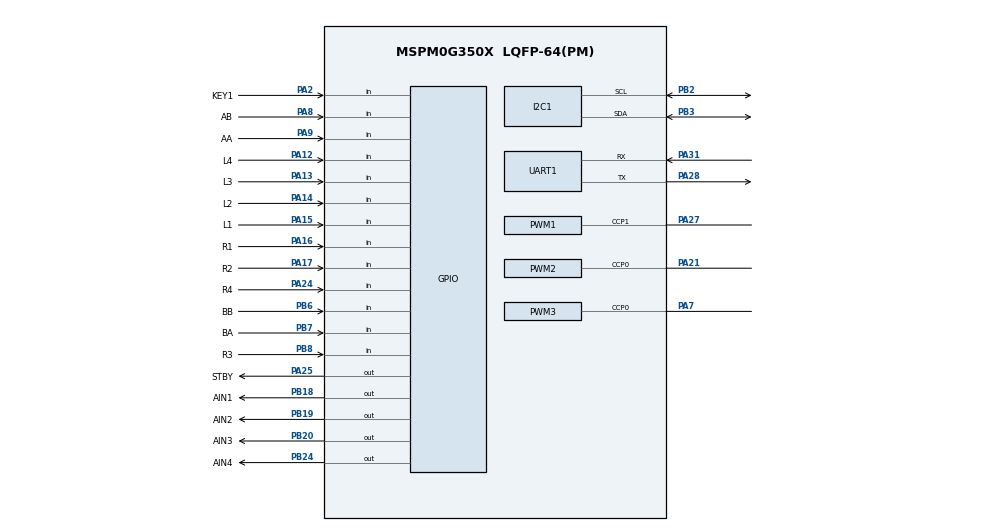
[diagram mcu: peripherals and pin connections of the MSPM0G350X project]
/**
 * @cliArgs --device "MSPM0G350X" --part "Default" --package "LQFP-64(PM)" --product "mspm0_sdk@2.10.00.04"
 * @versions {"tool":"1.26.2+4477"}
 */

/**
 * Import the modules used in this configuration.
 */
const GPIO   = scripting.addModule("/ti/driverlib/GPIO", {}, false);
const GPIO1  = GPIO.addInstance();
const GPIO2  = GPIO.addInstance();
const GPIO3  = GPIO.addInstance();
const GPIO4  = GPIO.addInstance();
const I2C    = scripting.addModule("/ti/driverlib/I2C", {}, false);
const I2C1   = I2C.addInstance();
const I2C2   = I2C.addInstance();
const PWM    = scripting.addModule("/ti/driverlib/PWM", {}, false);
const PWM1   = PWM.addInstance();
const PWM2   = PWM.addInstance();
const PWM3   = PWM.addInstance();
const SYSCTL = scripting.addModule("/ti/driverlib/SYSCTL");
const TIMER  = scripting.addModule("/ti/driverlib/TIMER", {}, false);
const TIMER1 = TIMER.addInstance();
const UART   = scripting.addModule("/ti/driverlib/UART", {}, false);
const UART1  = UART.addInstance();
const VREF   = scripting.addModule("/ti/driverlib/VREF");

/**
 * Write custom configuration values to the imported modules.
 */
const divider9       = system.clockTree["UDIV"];
divider9.divideValue = 2;

const multiplier2         = system.clockTree["PLL_QDIV"];
multiplier2.multiplyValue = 5;

const mux4       = system.clockTree["EXHFMUX"];
mux4.inputSelect = "EXHFMUX_XTAL";

const mux8       = system.clockTree["HSCLKMUX"];
mux8.inputSelect = "HSCLKMUX_SYSPLL0";

const pinFunction4     = system.clockTree["HFXT"];
pinFunction4.inputFreq = 40;
pinFunction4.enable    = true;

GPIO1.$name                              = "KEY";
GPIO1.associatedPins[0].direction        = "INPUT";
GPIO1.associatedPins[0].internalResistor = "PULL_DOWN";
GPIO1.associatedPins[0].interruptEn      = true;
GPIO1.associatedPins[0].polarity         = "RISE";
GPIO1.associatedPins[0].$name            = "KEY1";
GPIO1.associatedPins[0].pin.$assign      = "PA2";

const Board = scripting.addModule("/ti/driverlib/Board", {}, false);

GPIO2.$name                              = "DC_MOTOR_LEFT";
GPIO2.associatedPins.create(5);
GPIO2.associatedPins[0].$name            = "AIN1";
GPIO2.associatedPins[0].pin.$assign      = "PB18";
GPIO2.associatedPins[1].$name            = "AIN2";
GPIO2.associatedPins[1].pin.$assign      = "PB19";
GPIO2.associatedPins[2].$name            = "STBY";
GPIO2.associatedPins[2].pin.$assign      = "PA25";
GPIO2.associatedPins[3].$name            = "AA";
GPIO2.associatedPins[3].direction        = "INPUT";
GPIO2.associatedPins[3].internalResistor = "PULL_DOWN";
GPIO2.associatedPins[3].interruptEn      = true;
GPIO2.associatedPins[3].polarity         = "RISE";
GPIO2.associatedPins[3].pin.$assign      = "PA9";
GPIO2.associatedPins[4].$name            = "AB";
GPIO2.associatedPins[4].direction        = "INPUT";
GPIO2.associatedPins[4].internalResistor = "PULL_DOWN";
GPIO2.associatedPins[4].pin.$assign      = "PA8";

GPIO3.$name                              = "DC_MOTOR_RIGHT";
GPIO3.associatedPins.create(4);
GPIO3.associatedPins[0].$name            = "AIN3";
GPIO3.associatedPins[0].pin.$assign      = "PB20";
GPIO3.associatedPins[1].$name            = "AIN4";
GPIO3.associatedPins[1].pin.$assign      = "PB24";
GPIO3.associatedPins[2].$name            = "BA";
GPIO3.associatedPins[2].direction        = "INPUT";
GPIO3.associatedPins[2].polarity         = "RISE";
GPIO3.associatedPins[2].internalResistor = "PULL_DOWN";
GPIO3.associatedPins[2].interruptEn      = true;
GPIO3.associatedPins[2].pin.$assign      = "PB7";
GPIO3.associatedPins[3].$name            = "BB";
GPIO3.associatedPins[3].internalResistor = "PULL_DOWN";
GPIO3.associatedPins[3].direction        = "INPUT";
GPIO3.associatedPins[3].pin.$assign      = "PB6";

GPIO4.$name                         = "HUI_DU";
GPIO4.associatedPins.create(8);
GPIO4.associatedPins[0].$name       = "L4";
GPIO4.associatedPins[0].direction   = "INPUT";
GPIO4.associatedPins[0].pin.$assign = "PA12";
GPIO4.associatedPins[1].$name       = "L3";
GPIO4.associatedPins[1].direction   = "INPUT";
GPIO4.associatedPins[1].pin.$assign = "PA13";
GPIO4.associatedPins[2].$name       = "L2";
GPIO4.associatedPins[2].direction   = "INPUT";
GPIO4.associatedPins[2].pin.$assign = "PA14";
GPIO4.associatedPins[3].$name       = "L1";
GPIO4.associatedPins[3].direction   = "INPUT";
GPIO4.associatedPins[3].pin.$assign = "PA15";
GPIO4.associatedPins[4].$name       = "R1";
GPIO4.associatedPins[4].direction   = "INPUT";
GPIO4.associatedPins[4].pin.$assign = "PA16";
GPIO4.associatedPins[5].$name       = "R2";
GPIO4.associatedPins[5].direction   = "INPUT";
GPIO4.associatedPins[5].pin.$assign = "PA17";
GPIO4.associatedPins[6].$name       = "R3";
GPIO4.associatedPins[6].direction   = "INPUT";
GPIO4.associatedPins[6].pin.$assign = "PB8";
GPIO4.associatedPins[7].$name       = "R4";
GPIO4.associatedPins[7].direction   = "INPUT";
GPIO4.associatedPins[7].pin.$assign = "PA24";

I2C1.$name                             = "OLED";
I2C1.basicEnableController             = true;
I2C1.advDigitalGlitchFilter            = "CLOCKS_1";
I2C1.advControllerRXFIFOTRIG           = "BYTES_8";
I2C1.advControllerTXFIFOTRIG           = "BYTES_7";
I2C1.enableDMAEvent1                   = false;
I2C1.enableDMAEvent2                   = false;
I2C1.peripheral.sdaPin.$assign         = "PB3";
I2C1.peripheral.sclPin.$assign         = "PB2";
I2C1.sdaPinConfig.$name                = "ti_driverlib_gpio_GPIOPinGeneric0";
I2C1.sdaPinConfig.hideOutputInversion  = scripting.forceWrite(false);
I2C1.sdaPinConfig.onlyInternalResistor = scripting.forceWrite(false);
I2C1.sdaPinConfig.passedPeripheralType = scripting.forceWrite("Digital");
I2C1.sdaPinConfig.enableConfig         = true;
I2C1.sdaPinConfig.internalResistor     = "PULL_UP";
I2C1.sclPinConfig.$name                = "ti_driverlib_gpio_GPIOPinGeneric1";
I2C1.sclPinConfig.hideOutputInversion  = scripting.forceWrite(false);
I2C1.sclPinConfig.onlyInternalResistor = scripting.forceWrite(false);
I2C1.sclPinConfig.passedPeripheralType = scripting.forceWrite("Digital");
I2C1.sclPinConfig.enableConfig         = true;
I2C1.sclPinConfig.internalResistor     = "PULL_UP";

I2C2.$name                             = "MPU6050";
I2C2.sdaPinConfig.$name                = "ti_driverlib_gpio_GPIOPinGeneric6";
I2C2.sdaPinConfig.hideOutputInversion  = scripting.forceWrite(false);
I2C2.sdaPinConfig.onlyInternalResistor = scripting.forceWrite(false);
I2C2.sdaPinConfig.passedPeripheralType = scripting.forceWrite("Digital");
I2C2.sclPinConfig.$name                = "ti_driverlib_gpio_GPIOPinGeneric9";
I2C2.sclPinConfig.hideOutputInversion  = scripting.forceWrite(false);
I2C2.sclPinConfig.onlyInternalResistor = scripting.forceWrite(false);
I2C2.sclPinConfig.passedPeripheralType = scripting.forceWrite("Digital");

PWM1.$name                              = "SERVO";
PWM1.clockDivider                       = 8;
PWM1.clockPrescale                      = 100;
PWM1.pwmMode                            = "EDGE_ALIGN_UP";
PWM1.ccIndex                            = [1];
PWM1.timerCount                         = 2000;
PWM1.timerStartTimer                    = true;
PWM1.ccp1PinConfig.direction            = scripting.forceWrite("OUTPUT");
PWM1.ccp1PinConfig.hideOutputInversion  = scripting.forceWrite(false);
PWM1.ccp1PinConfig.onlyInternalResistor = scripting.forceWrite(false);
PWM1.ccp1PinConfig.passedPeripheralType = scripting.forceWrite("Digital");
PWM1.ccp1PinConfig.$name                = "ti_driverlib_gpio_GPIOPinGeneric7";
PWM1.peripheral.$assign                 = "TIMG7";
PWM1.peripheral.ccp1Pin.$assign         = "PA27";
PWM1.PWM_CHANNEL_1.$name                = "ti_driverlib_pwm_PWMTimerCC0";
PWM1.PWM_CHANNEL_1.dutyCycle            = 7.5;

PWM2.$name                      = "PWMA";
PWM2.timerStartTimer            = true;
PWM2.timerCount                 = 4000;
PWM2.pwmMode                    = "EDGE_ALIGN_UP";
PWM2.ccIndex                    = [0];
PWM2.PWM_CHANNEL_0.$name        = "ti_driverlib_pwm_PWMTimerCC1";
PWM2.ccp0PinConfig.$name        = "ti_driverlib_gpio_GPIOPinGeneric10";
PWM2.peripheral.$assign         = "TIMG6";
PWM2.peripheral.ccp0Pin.$assign = "PA21";

PWM3.ccIndex                            = [0];
PWM3.timerStartTimer                    = true;
PWM3.timerCount                         = 4000;
PWM3.pwmMode                            = "EDGE_ALIGN_UP";
PWM3.$name                              = "PWMB";
PWM3.PWM_CHANNEL_0.$name                = "ti_driverlib_pwm_PWMTimerCC2";
PWM3.ccp0PinConfig.direction            = scripting.forceWrite("OUTPUT");
PWM3.ccp0PinConfig.hideOutputInversion  = scripting.forceWrite(false);
PWM3.ccp0PinConfig.onlyInternalResistor = scripting.forceWrite(false);
PWM3.ccp0PinConfig.passedPeripheralType = scripting.forceWrite("Digital");
PWM3.ccp0PinConfig.$name                = "ti_driverlib_gpio_GPIOPinGeneric8";
PWM3.peripheral.ccp0Pin.$assign         = "PA7";

SYSCTL.forceDefaultClkConfig = true;
SYSCTL.clockTreeEn           = true;

TIMER1.$name              = "PID";
TIMER1.timerMode          = "PERIODIC_UP";
TIMER1.timerClkDiv        = 5;
TIMER1.timerClkPrescale   = 16;
TIMER1.interrupts         = ["LOAD"];
TIMER1.timerPeriod        = "10 ms";
TIMER1.peripheral.$assign = "TIMA0";

UART1.targetBaudRate                   = 115200;
UART1.enabledInterrupts                = ["RX"];
UART1.$name                            = "PRINT";
UART1.peripheral.rxPin.$assign         = "PA31";
UART1.peripheral.txPin.$assign         = "PA28";
UART1.txPinConfig.direction            = scripting.forceWrite("OUTPUT");
UART1.txPinConfig.hideOutputInversion  = scripting.forceWrite(false);
UART1.txPinConfig.onlyInternalResistor = scripting.forceWrite(false);
UART1.txPinConfig.passedPeripheralType = scripting.forceWrite("Digital");
UART1.txPinConfig.$name                = "ti_driverlib_gpio_GPIOPinGeneric2";
UART1.rxPinConfig.hideOutputInversion  = scripting.forceWrite(false);
UART1.rxPinConfig.onlyInternalResistor = scripting.forceWrite(false);
UART1.rxPinConfig.passedPeripheralType = scripting.forceWrite("Digital");
UART1.rxPinConfig.$name                = "ti_driverlib_gpio_GPIOPinGeneric3";

VREF.basicIntVolt           = "DL_VREF_BUFCONFIG_OUTPUT_2_5V";
VREF.profile                = "INT_2_5_V";
VREF.vrefPosPinConfig.$name = "ti_driverlib_gpio_GPIOPinGeneric5";

/**
 * Pinmux solution for unlocked pins/peripherals. This ensures that minor changes to the automatic solver in a future
 * version of the tool will not impact the pinmux you originally saw.  These lines can be completely deleted in order to
 * re-solve from scratch.
 */
pinFunction4.peripheral.$suggestSolution           = "SYSCTL";
pinFunction4.peripheral.hfxInPin.$suggestSolution  = "PA5";
pinFunction4.peripheral.hfxOutPin.$suggestSolution = "PA6";
Board.peripheral.$suggestSolution                  = "DEBUGSS";
Board.peripheral.swclkPin.$suggestSolution         = "PA20";
Board.peripheral.swdioPin.$suggestSolution         = "PA19";
I2C1.peripheral.$suggestSolution                   = "I2C1";
I2C2.peripheral.$suggestSolution                   = "I2C0";
I2C2.peripheral.sdaPin.$suggestSolution            = "PA0";
I2C2.peripheral.sclPin.$suggestSolution            = "PA1";
PWM3.peripheral.$suggestSolution                   = "TIMG8";
UART1.peripheral.$suggestSolution                  = "UART0";
VREF.peripheral.$suggestSolution                   = "VREF";
VREF.peripheral.vrefPosPin.$suggestSolution        = "PA23";
